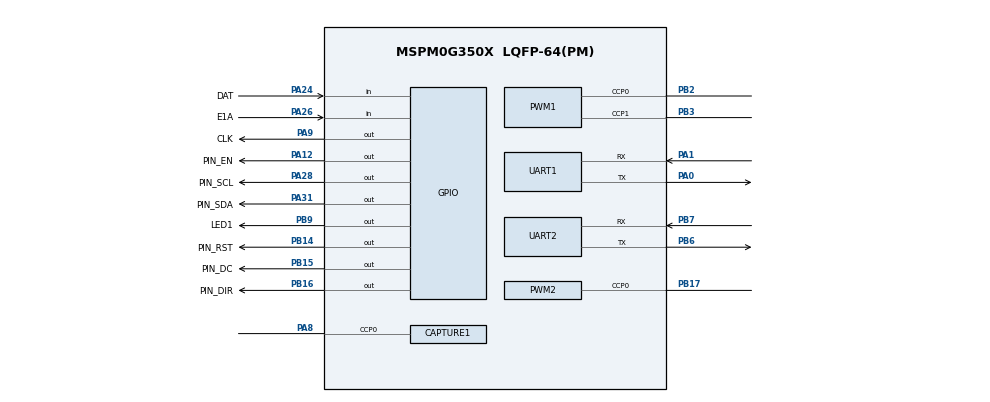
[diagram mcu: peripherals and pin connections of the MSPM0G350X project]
/**
 * @cliArgs --device "MSPM0G350X" --part "Default" --package "LQFP-64(PM)" --product "mspm0_sdk@2.10.00.04"
 * @versions {"tool":"1.27.0+4565"}
 */

/**
 * Import the modules used in this configuration.
 */
const GPIO     = scripting.addModule("/ti/driverlib/GPIO", {}, false);
const GPIO1    = GPIO.addInstance();
const GPIO2    = GPIO.addInstance();
const GPIO3    = GPIO.addInstance();
const GPIO4    = GPIO.addInstance();
const GPIO5    = GPIO.addInstance();
const GPIO6    = GPIO.addInstance();
const GPIO7    = GPIO.addInstance();
const GPIO8    = GPIO.addInstance();
const GPIO9    = GPIO.addInstance();
const GPIO10   = GPIO.addInstance();
const GPIO11   = GPIO.addInstance();
const CAPTURE  = scripting.addModule("/ti/driverlib/CAPTURE", {}, false);
const CAPTURE1 = CAPTURE.addInstance();
const PWM      = scripting.addModule("/ti/driverlib/PWM", {}, false);
const PWM1     = PWM.addInstance();
const PWM2     = PWM.addInstance();
const SYSCTL   = scripting.addModule("/ti/driverlib/SYSCTL");
const SYSTICK  = scripting.addModule("/ti/driverlib/SYSTICK");
const UART     = scripting.addModule("/ti/driverlib/UART", {}, false);
const UART1    = UART.addInstance();
const UART2    = UART.addInstance();

/**
 * Write custom configuration values to the imported modules.
 */
const divider6       = system.clockTree["PLL_CLK2X_DIV"];
divider6.divideValue = 4;

const divider7       = system.clockTree["PLL_PDIV"];
divider7.divideValue = 2;

const divider9       = system.clockTree["UDIV"];
divider9.divideValue = 2;

const multiplier2         = system.clockTree["PLL_QDIV"];
multiplier2.multiplyValue = 10;

const mux8       = system.clockTree["HSCLKMUX"];
mux8.inputSelect = "HSCLKMUX_SYSPLL2X";

const Board = scripting.addModule("/ti/driverlib/Board", {}, false);

GPIO1.$name                          = "AIN";
GPIO1.port                           = "PORTA";
GPIO1.associatedPins.create(2);
GPIO1.associatedPins[0].initialValue = "SET";
GPIO1.associatedPins[0].assignedPin  = "14";
GPIO1.associatedPins[0].$name        = "AIN2";
GPIO1.associatedPins[1].initialValue = "SET";
GPIO1.associatedPins[1].assignedPin  = "13";
GPIO1.associatedPins[1].$name        = "AIN1";

GPIO2.$name                          = "BIN";
GPIO2.port                           = "PORTA";
GPIO2.associatedPins.create(2);
GPIO2.associatedPins[0].initialValue = "SET";
GPIO2.associatedPins[0].assignedPin  = "16";
GPIO2.associatedPins[0].$name        = "BIN2";
GPIO2.associatedPins[1].initialValue = "SET";
GPIO2.associatedPins[1].assignedPin  = "17";
GPIO2.associatedPins[1].$name        = "BIN1";

GPIO3.$name                          = "LED";
GPIO3.associatedPins[0].$name        = "LED1";
GPIO3.associatedPins[0].initialValue = "SET";
GPIO3.associatedPins[0].assignedPort = "PORTB";
GPIO3.associatedPins[0].assignedPin  = "9";
GPIO3.associatedPins[0].pin.$assign  = "PB9";

GPIO4.$name                          = "ENCODER";
GPIO4.associatedPins.create(4);
GPIO4.associatedPins[0].direction    = "INPUT";
GPIO4.associatedPins[0].interruptEn  = true;
GPIO4.associatedPins[0].polarity     = "RISE_FALL";
GPIO4.associatedPins[0].assignedPin  = "25";
GPIO4.associatedPins[0].$name        = "E1B";
GPIO4.associatedPins[1].direction    = "INPUT";
GPIO4.associatedPins[1].interruptEn  = true;
GPIO4.associatedPins[1].polarity     = "RISE_FALL";
GPIO4.associatedPins[1].assignedPin  = "26";
GPIO4.associatedPins[1].$name        = "E1A";
GPIO4.associatedPins[1].pin.$assign  = "PA26";
GPIO4.associatedPins[2].direction    = "INPUT";
GPIO4.associatedPins[2].interruptEn  = true;
GPIO4.associatedPins[2].polarity     = "RISE_FALL";
GPIO4.associatedPins[2].assignedPort = "PORTB";
GPIO4.associatedPins[2].assignedPin  = "20";
GPIO4.associatedPins[2].$name        = "E2B";
GPIO4.associatedPins[3].direction    = "INPUT";
GPIO4.associatedPins[3].interruptEn  = true;
GPIO4.associatedPins[3].polarity     = "RISE_FALL";
GPIO4.associatedPins[3].assignedPort = "PORTB";
GPIO4.associatedPins[3].assignedPin  = "24";
GPIO4.associatedPins[3].$name        = "E2A";

GPIO5.$name                          = "GRAY_SERIAL";
GPIO5.associatedPins.create(2);
GPIO5.associatedPins[0].$name        = "DAT";
GPIO5.associatedPins[0].direction    = "INPUT";
GPIO5.associatedPins[0].assignedPort = "PORTA";
GPIO5.associatedPins[0].assignedPin  = "24";
GPIO5.associatedPins[0].pin.$assign  = "PA24";
GPIO5.associatedPins[1].$name        = "CLK";
GPIO5.associatedPins[1].initialValue = "SET";
GPIO5.associatedPins[1].assignedPort = "PORTA";
GPIO5.associatedPins[1].assignedPin  = "9";
GPIO5.associatedPins[1].pin.$assign  = "PA9";

GPIO6.$name                          = "OLED_RST";
GPIO6.associatedPins[0].$name        = "PIN_RST";
GPIO6.associatedPins[0].initialValue = "SET";
GPIO6.associatedPins[0].assignedPort = "PORTB";
GPIO6.associatedPins[0].assignedPin  = "14";
GPIO6.associatedPins[0].pin.$assign  = "PB14";

GPIO7.$name                          = "OLED_DC";
GPIO7.associatedPins[0].$name        = "PIN_DC";
GPIO7.associatedPins[0].initialValue = "SET";
GPIO7.associatedPins[0].assignedPort = "PORTB";
GPIO7.associatedPins[0].assignedPin  = "15";
GPIO7.associatedPins[0].pin.$assign  = "PB15";

GPIO8.$name                          = "OLED_SCL";
GPIO8.associatedPins[0].$name        = "PIN_SCL";
GPIO8.associatedPins[0].initialValue = "SET";
GPIO8.associatedPins[0].assignedPort = "PORTA";
GPIO8.associatedPins[0].assignedPin  = "28";
GPIO8.associatedPins[0].pin.$assign  = "PA28";

GPIO9.$name                          = "OLED_SDA";
GPIO9.associatedPins[0].$name        = "PIN_SDA";
GPIO9.associatedPins[0].initialValue = "SET";
GPIO9.associatedPins[0].assignedPort = "PORTA";
GPIO9.associatedPins[0].assignedPin  = "31";
GPIO9.associatedPins[0].pin.$assign  = "PA31";

GPIO10.$name                          = "STEPPER_DIR";
GPIO10.associatedPins[0].$name        = "PIN_DIR";
GPIO10.associatedPins[0].direction    = "OUTPUT";
GPIO10.associatedPins[0].initialValue = "CLEARED";
GPIO10.associatedPins[0].assignedPort = "PORTB";
GPIO10.associatedPins[0].assignedPin  = "16";
GPIO10.associatedPins[0].pin.$assign  = "PB16";

GPIO11.$name                          = "STEPPER_EN";
GPIO11.associatedPins[0].$name        = "PIN_EN";
GPIO11.associatedPins[0].direction    = "OUTPUT";
GPIO11.associatedPins[0].initialValue = "CLEARED";
GPIO11.associatedPins[0].assignedPort = "PORTA";
GPIO11.associatedPins[0].assignedPin  = "12";
GPIO11.associatedPins[0].pin.$assign  = "PA12";

PWM1.$name                              = "PWM";
PWM1.timerCount                         = 4000;
PWM1.timerStartTimer                    = true;
PWM1.peripheral.$assign                 = "TIMG6";
PWM1.peripheral.ccp0Pin.$assign         = "PB2";
PWM1.peripheral.ccp1Pin.$assign         = "PB3";
PWM1.PWM_CHANNEL_0.$name                = "ti_driverlib_pwm_PWMTimerCC0";
PWM1.PWM_CHANNEL_0.ccValue              = 2000;
PWM1.PWM_CHANNEL_0.invert               = true;
PWM1.PWM_CHANNEL_1.$name                = "ti_driverlib_pwm_PWMTimerCC1";
PWM1.PWM_CHANNEL_1.invert               = true;
PWM1.PWM_CHANNEL_1.ccValue              = 2000;
PWM1.ccp0PinConfig.direction            = scripting.forceWrite("OUTPUT");
PWM1.ccp0PinConfig.hideOutputInversion  = scripting.forceWrite(false);
PWM1.ccp0PinConfig.onlyInternalResistor = scripting.forceWrite(false);
PWM1.ccp0PinConfig.passedPeripheralType = scripting.forceWrite("Digital");
PWM1.ccp0PinConfig.$name                = "ti_driverlib_gpio_GPIOPinGeneric0";
PWM1.ccp1PinConfig.direction            = scripting.forceWrite("OUTPUT");
PWM1.ccp1PinConfig.hideOutputInversion  = scripting.forceWrite(false);
PWM1.ccp1PinConfig.onlyInternalResistor = scripting.forceWrite(false);
PWM1.ccp1PinConfig.passedPeripheralType = scripting.forceWrite("Digital");
PWM1.ccp1PinConfig.$name                = "ti_driverlib_gpio_GPIOPinGeneric1";

PWM2.$name                              = "STEPPER_PWM";
PWM2.ccIndex                            = [0];
PWM2.clockPrescale                      = 80;
PWM2.timerCount                         = 1000;
PWM2.timerStartTimer                    = false;
PWM2.peripheral.$assign                 = "TIMA1";
PWM2.peripheral.ccp0Pin.$assign         = "PB17";
PWM2.PWM_CHANNEL_0.$name                = "STEPPER_PWM_CHANNEL_0";
PWM2.PWM_CHANNEL_0.ccValue              = 500;
PWM2.ccp0PinConfig.direction            = scripting.forceWrite("OUTPUT");
PWM2.ccp0PinConfig.hideOutputInversion  = scripting.forceWrite(false);
PWM2.ccp0PinConfig.onlyInternalResistor = scripting.forceWrite(false);
PWM2.ccp0PinConfig.passedPeripheralType = scripting.forceWrite("Digital");
PWM2.ccp0PinConfig.$name                = "ti_driverlib_gpio_GPIOPinGeneric8";

CAPTURE1.$name                      = "BEAM_ENCODER_PWM";
CAPTURE1.ccIndex                    = 0;
CAPTURE1.captMode                   = "COMBINED";
CAPTURE1.timerClkPrescale           = 80;
CAPTURE1.timerPeriod                = "65 ms";
CAPTURE1.interrupts                 = ["CC1_DN","ZERO"];
CAPTURE1.peripheral.$assign         = "TIMA0";
CAPTURE1.peripheral.ccp0Pin.$assign = "PA8";
CAPTURE1.ccp0PinConfig.$name        = "BEAM_ENCODER_PWM_PIN";

SYSCTL.forceDefaultClkConfig = true;
SYSCTL.clockTreeEn           = true;

SYSTICK.periodEnable    = true;
SYSTICK.interruptEnable = true;
SYSTICK.period          = 80000;
SYSTICK.systickEnable   = true;

UART1.$name                            = "UART0";
UART1.targetBaudRate                   = 115200;
UART1.peripheral.$assign               = "UART0";
UART1.peripheral.rxPin.$assign         = "PA1";
UART1.peripheral.txPin.$assign         = "PA0";
UART1.txPinConfig.direction            = scripting.forceWrite("OUTPUT");
UART1.txPinConfig.hideOutputInversion  = scripting.forceWrite(false);
UART1.txPinConfig.onlyInternalResistor = scripting.forceWrite(false);
UART1.txPinConfig.passedPeripheralType = scripting.forceWrite("Digital");
UART1.txPinConfig.$name                = "ti_driverlib_gpio_GPIOPinGeneric2";
UART1.rxPinConfig.hideOutputInversion  = scripting.forceWrite(false);
UART1.rxPinConfig.onlyInternalResistor = scripting.forceWrite(false);
UART1.rxPinConfig.passedPeripheralType = scripting.forceWrite("Digital");
UART1.rxPinConfig.$name                = "ti_driverlib_gpio_GPIOPinGeneric3";

UART2.$name                    = "UART_1";
UART2.targetBaudRate           = 115200;
UART2.enabledInterrupts        = ["RX"];
UART2.interruptPriority        = "1";
UART2.peripheral.$assign       = "UART1";
UART2.peripheral.rxPin.$assign = "PB7";
UART2.peripheral.txPin.$assign = "PB6";
UART2.txPinConfig.$name        = "ti_driverlib_gpio_GPIOPinGeneric6";
UART2.rxPinConfig.$name        = "ti_driverlib_gpio_GPIOPinGeneric7";

/**
 * Pinmux solution for unlocked pins/peripherals. This ensures that minor changes to the automatic solver in a future
 * version of the tool will not impact the pinmux you originally saw.  These lines can be completely deleted in order to
 * re-solve from scratch.
 */
PWM2.peripheral.$suggestSolution            = "TIMA1";
CAPTURE1.peripheral.$suggestSolution         = "TIMA0";
Board.peripheral.$suggestSolution            = "DEBUGSS";
Board.peripheral.swclkPin.$suggestSolution   = "PA20";
Board.peripheral.swdioPin.$suggestSolution   = "PA19";
GPIO1.associatedPins[0].pin.$suggestSolution = "PA14";
GPIO1.associatedPins[1].pin.$suggestSolution = "PA13";
GPIO2.associatedPins[0].pin.$suggestSolution = "PA16";
GPIO2.associatedPins[1].pin.$suggestSolution = "PA17";
GPIO4.associatedPins[0].pin.$suggestSolution = "PA25";
GPIO4.associatedPins[2].pin.$suggestSolution = "PB20";
GPIO4.associatedPins[3].pin.$suggestSolution = "PB24";
